# STM32F303 register map
File version: 1.4
CPU: CM4 r1p0, little endian, no MPU, no FPU, 4 interrupt priority bits
Registers are 32-bit, read-write, reset 0x0 unless marked. A register's access mark holds for its fields unless they carry their own. Offsets are from the block's base; [hi:lo] are bit positions; lines under a group give offsets from that group; {n}, {i} and the like mark numbered series; 'fields as' and 'values as' point back to an identical list.

## TSC — Touch sensing controller
Base 0x40024000
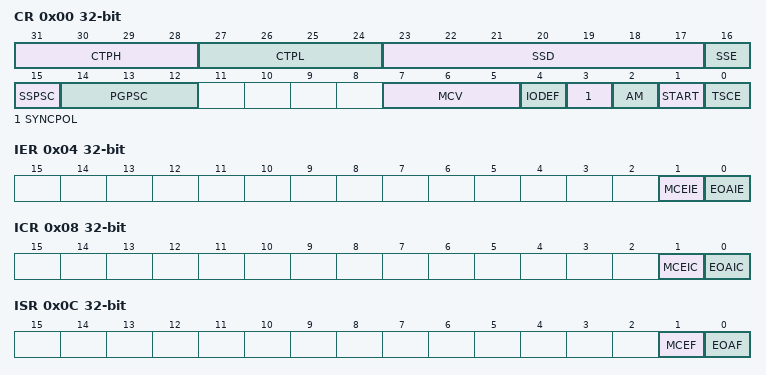
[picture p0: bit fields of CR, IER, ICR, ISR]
0x00 CR — control register
  [31:28] CTPH — Charge transfer pulse high
  [27:24] CTPL — Charge transfer pulse low
  [23:17] SSD — Spread spectrum deviation
  [16] SSE — Spread spectrum enable
  [15] SSPSC — Spread spectrum prescaler
  [14:12] PGPSC — pulse generator prescaler
  [7:5] MCV — Max count value
  [4] IODEF — I/O Default mode
  [3] SYNCPOL — Synchronization pin polarity
  [2] AM — Acquisition mode
  [1] START — Start a new acquisition
  [0] TSCE — Touch sensing controller enable
0x04 IER — interrupt enable register
  [1] MCEIE — Max count error interrupt enable
  [0] EOAIE — End of acquisition interrupt enable
0x08 ICR — interrupt clear register
  [1] MCEIC — Max count error interrupt clear
  [0] EOAIC — End of acquisition interrupt clear
0x0C ISR — interrupt status register
  [1] MCEF — Max count error flag
  [0] EOAF — End of acquisition flag
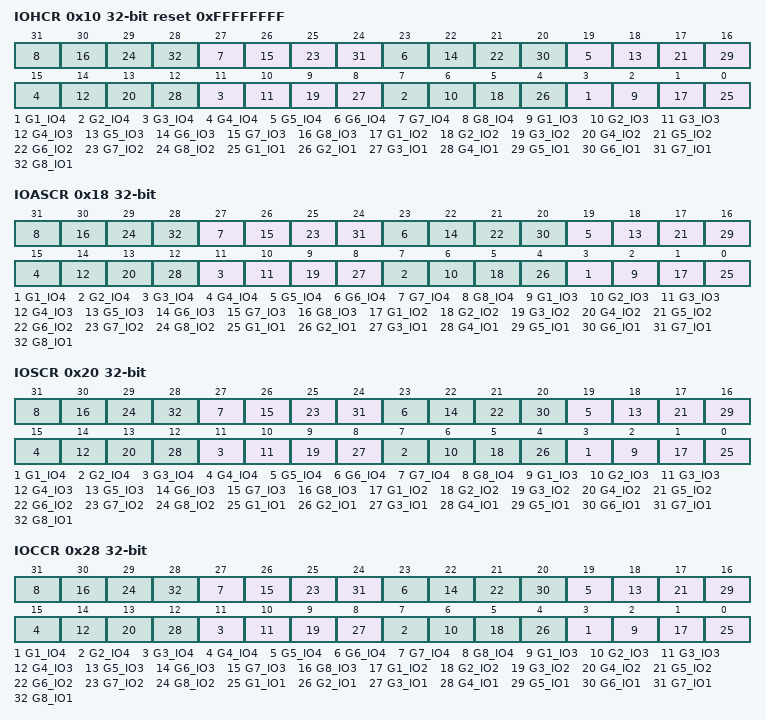
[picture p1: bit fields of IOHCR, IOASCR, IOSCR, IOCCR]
0x10 IOHCR reset 0xFFFFFFFF — I/O hysteresis control register
  [4n-1] G{n}_IO4 (n=1..8) — G{n}_IO4 Schmitt trigger hysteresis mode
  [4n-2] G{n}_IO3 (n=1..8) — G{n}_IO3 Schmitt trigger hysteresis mode
  [4n-3] G{n}_IO2 (n=1..8) — G{n}_IO2 Schmitt trigger hysteresis mode
  [4n-4] G{n}_IO1 (n=1..8) — G{n}_IO1 Schmitt trigger hysteresis mode
0x18 IOASCR — I/O analog switch control register
  [4n-1] G{n}_IO4 (n=1..8) — G{n}_IO4 analog switch enable
  [4n-2] G{n}_IO3 (n=1..8) — G{n}_IO3 analog switch enable
  [4n-3] G{n}_IO2 (n=1..8) — G{n}_IO2 analog switch enable
  [4n-4] G{n}_IO1 (n=1..8) — G{n}_IO1 analog switch enable
0x20 IOSCR — I/O sampling control register
  [4n-1] G{n}_IO4 (n=1..8) — G{n}_IO4 sampling mode
  [4n-2] G{n}_IO3 (n=1..8) — G{n}_IO3 sampling mode
  [4n-3] G{n}_IO2 (n=1..8) — G{n}_IO2 sampling mode
  [4n-4] G{n}_IO1 (n=1..8) — G{n}_IO1 sampling mode
0x28 IOCCR — I/O channel control register
  [4n-1] G{n}_IO4 (n=1..8) — G{n}_IO4 channel mode
  [4n-2] G{n}_IO3 (n=1..8) — G{n}_IO3 channel mode
  [4n-3] G{n}_IO2 (n=1..8) — G{n}_IO2 channel mode
  [4n-4] G{n}_IO1 (n=1..8) — G{n}_IO1 channel mode
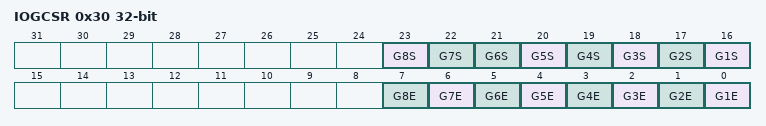
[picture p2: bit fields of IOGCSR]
0x30 IOGCSR access per field — I/O group control status register
  [23] G8S rw — Analog I/O group x status
  [22] G7S rw — Analog I/O group x status
  [n+15] G{n}S ro (n=1..6) — Analog I/O group x status
  [n-1] G{n}E rw (n=1..8) — Analog I/O group x enable
{0x30+4i} IOG{i}CR (i=1..8) ro — I/O group x counter register
  [13:0] CNT — Counter value

## CRC — cyclic redundancy check calculation unit
Base 0x40023000
0x00 DR reset 0xFFFFFFFF — Data register
  [31:0] DR — Data register bits
0x00 DR8 8-bit reset 0xFF (alternate view of DR) — Data register - byte sized
  [7:0] DR8 — Data register bits
0x00 DR16 16-bit reset 0xFFFF (alternate view of DR) — Data register - half-word sized
  [15:0] DR16 — Data register bits
0x04 IDR — Independent data register
  [7:0] IDR — General-purpose 8-bit data register bits
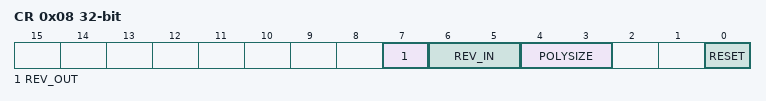
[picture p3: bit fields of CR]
0x08 CR — Control register
  [7] REV_OUT — Reverse output data
    0=Normal (Bit order not affected); 1=Reversed (Bit reversed output)
  [6:5] REV_IN — Reverse input data
    0=Normal (Bit order not affected); 1=Byte (Bit reversal done by byte); 2=HalfWord (Bit reversal done by half-word); 3=Word (Bit reversal done by word)
  [4:3] POLYSIZE — Polynomial size
    0=32-bit polynomial; 1=16-bit polynomial; 2=8-bit polynomial; 3=7-bit polynomial
  [0] RESET — reset bit
    on write: 1=Resets the CRC calculation unit and sets the data register to 0xFFFF FFFF
0x10 INIT reset 0xFFFFFFFF — Initial CRC value
  [31:0] INIT — Programmable initial CRC value
0x14 POL reset 0x4C11DB7 — CRC polynomial
  [31:0] POL — Programmable polynomial

## DMA1 — DMA controller 1
Base 0x40020000
Same registers: DMA2 0x40020400
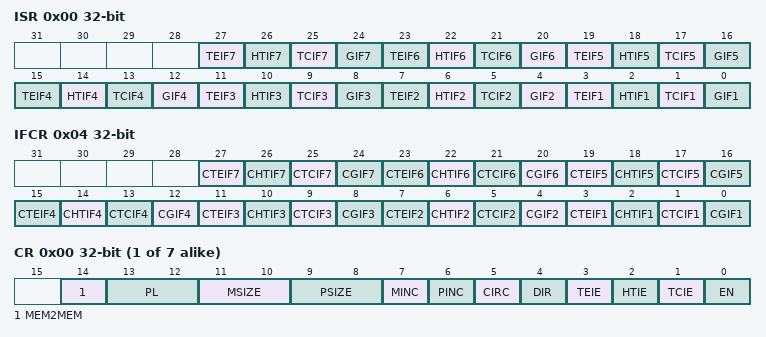
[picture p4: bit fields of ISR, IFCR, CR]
0x00 ISR ro — DMA interrupt status register (DMA_ISR)
  [4n-1] TEIF{n} (n=1..7) — Channel {n} Transfer Error flag
    0=NoError (No transfer error); 1=Error (A transfer error has occured)
  [4n-2] HTIF{n} (n=1..7) — Channel {n} Half Transfer Complete flag
    0=NotHalf (No half transfer event); 1=Half (A half transfer event has occured)
  [4n-3] TCIF{n} (n=1..7) — Channel {n} Transfer Complete flag
    0=NotComplete (No transfer complete event); 1=Complete (A transfer complete event has occured)
  [4n-4] GIF{n} (n=1..7) — Channel {n} Global interrupt flag
    0=NoEvent (No transfer error, half event, complete event); 1=Event (A transfer error, half event or complete event has occured)
0x04 IFCR wo — DMA interrupt flag clear register (DMA_IFCR)
  [4n-1] CTEIF{n} (n=1..7) — Channel {n} Transfer Error clear
    1=Clears the TEIF flag in the ISR register
  [4n-2] CHTIF{n} (n=1..7) — Channel {n} Half Transfer clear
    1=Clears the HTIF flag in the ISR register
  [4n-3] CTCIF{n} (n=1..7) — Channel {n} Transfer Complete clear
    1=Clears the TCIF flag in the ISR register
  [4n-4] CGIF{n} (n=1..7) — Channel {n} Global interrupt clear
    1=Clears the GIF, TEIF, HTIF, TCIF flags in the ISR register
0x08 CH{i} (i=1..7; step 0x14) group — Channel cluster: CCR?, CNDTR?, CPAR?, and CMAR? registers
  0x00 CR — DMA channel configuration register (DMA_CCR)
    [14] MEM2MEM — Memory to memory mode
      0=Disabled (Memory to memory mode disabled); 1=Enabled (Memory to memory mode enabled)
    [13:12] PL — Channel Priority level
      0=Low (Low priority); 1=Medium priority; 2=High priority; 3=Very high priority
    [11:10] MSIZE — Memory size
      0=Bits8 (8-bit size); 1=Bits16 (16-bit size); 2=Bits32 (32-bit size)
    [9:8] PSIZE — Peripheral size
      values as MSIZE
    [7] MINC — Memory increment mode
      0=Disabled (Increment mode disabled); 1=Enabled (Increment mode enabled)
    [6] PINC — Peripheral increment mode
      values as MINC
    [5] CIRC — Circular mode
      0=Disabled (Circular buffer disabled); 1=Enabled (Circular buffer enabled)
    [4] DIR — Data transfer direction
      0=FromPeripheral (Read from peripheral); 1=FromMemory (Read from memory)
    [3] TEIE — Transfer error interrupt enable
      0=Disabled (Transfer Error interrupt disabled); 1=Enabled (Transfer Error interrupt enabled)
    [2] HTIE — Half Transfer interrupt enable
      0=Disabled (Half Transfer interrupt disabled); 1=Enabled (Half Transfer interrupt enabled)
    [1] TCIE — Transfer complete interrupt enable
      0=Disabled (Transfer Complete interrupt disabled); 1=Enabled (Transfer Complete interrupt enabled)
    [0] EN — Channel enable
      0=Disabled (Channel disabled); 1=Enabled (Channel enabled)
  0x04 NDTR — DMA channel 1 number of data register
    [15:0] NDT — Number of data to transfer
  0x08 PAR — DMA channel 1 peripheral address register
    [31:0] PA — Peripheral address
  0x0C MAR — DMA channel 1 memory address register
    [31:0] MA — Memory address
